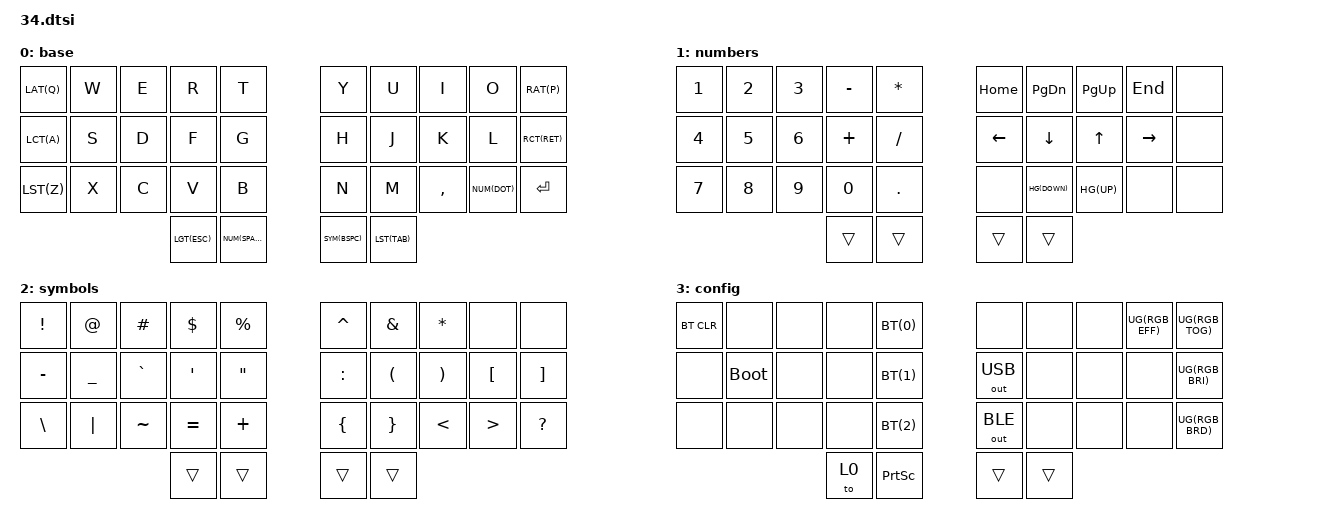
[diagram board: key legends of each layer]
#include <behaviors.dtsi>
#include <dt-bindings/zmk/backlight.h>
#include <dt-bindings/zmk/bt.h>
#include <dt-bindings/zmk/keys.h>
#include <dt-bindings/zmk/outputs.h>
#include <dt-bindings/zmk/rgb.h>

&caps_word {
    continue-list = <UNDERSCORE MINUS BSPC DEL N1 N2 N3 N4 N5 N6 N7 N8 N9 N0>;
};

// hold-prefered: trigger hold when other key is pressed
//      balanced: trigger hold when other key is pressed and released

&mt {
    flavor = "hold-preferred";
    tapping-term-ms = <200>;
    quick-tap-ms = <180>;
};

&lt {
    flavor = "balanced";
    tapping-term-ms = <200>;
    quick-tap-ms = <180>;
};


#define NUM(k1) &lt 1 k1
#define SYM(k1) &lt 2 k1
#define CFG(k1) &lt 3 k1

// alt/opt
#define LAT(k1) &ht LALT k1
#define RAT(k1) &ht RALT k1
// Gui/cmd/win
#define LGT(k1) &ht LGUI k1
// shift
#define LST(k1) &ht LSHFT k1
#define RST(k1) &ht RSHFT k1
// ctrl
#define LCT(k1) &ht LCTRL k1
#define RCT(k1) &ht RCTRL k1
// rgb
#define UG(k1) &rgb_ug k1

// Hold GUI + x key press
#define HG(k1) &kp LG(k1)
#define BT(k1) &bt BT_SEL k1
#define BTC &bt BT_CLR

#define BOOT &bootloader

//     == layout and key index ==
//
// +---------------+---------------+
// | 0  1  2  3  4 |  5  6  7  8  9|
// |10 11 12 13 14 | 15 16 17 18 19|
// |20 21 22 23 24 | 25 26 27 28 29|
// +--------|30 31 | 32 33|--------+
//          +------+------+
/ {
    combos {
        compatible = "zmk,combos";
        combo_bspc {
            bindings = <&kp BACKSPACE>;
            key-positions = <3 4>;
        };

        combo_vol_down {
            bindings = <&kp C_VOL_DN>;
            key-positions = <26 27>;
        };

        combo_vol_up {
            bindings = <&kp C_VOL_UP>;
            key-positions = <27 28>;
        };

        combo_caps_word {
            bindings = <&caps_word>;
            key-positions = <13 16>;
        };
        combo_sticky_ctrl_shift {
            bindings = <&sk LC(LSHFT)>;
            key-positions = <10 20>;
        };
        combo_layer_3 {
            bindings = <&to 3>;
            key-positions = <0 9>;
        };
    };

    behaviors {
        hp: hold_preferred {
            label = "HOLD PREFERRED";
            compatible = "zmk,behavior-hold-tap";
            #binding-cells = <2>;
            flavor = "hold-preferred";
            tapping-term-ms = <200>;
            quick-tap-ms = <180>;
            bindings = <&kp>, <&kp>;
        };
        ht: hold_tap {
            label = "TAP_HOLD";
            compatible = "zmk,behavior-hold-tap";
            #binding-cells = <2>;
            flavor = "balanced";
            tapping-term-ms = <200>;
            quick-tap-ms = <180>;
            bindings = <&kp>, <&kp>;
        };
        td0: td_0 {
            compatible = "zmk,behavior-tap-dance";
            label = "GUI_BACKTICK";
            #binding-cells = <0>;
            tapping-term-ms = <200>;
            bindings = <&kp LG(GRAVE)>;
        };
    };

//############################################################################################################
// * Having enter on left side to hit action when right hand operate mouse
//############################################################################################################

    keymap {
        compatible = "zmk,keymap";
        label = "3x5 keymap";

        base {
            bindings = <
//+---------+---------+---------+---------+---------+/*  */+---------+---------+---------+---------+---------+
   LAT(Q)    &kp W     &kp E     &kp R     &kp T     /*  */ &kp Y     &kp U     &kp I     &kp O     RAT(P)
//+---------+---------+---------+---------+---------+/*  */+---------+---------+---------+---------+---------+
   LCT(A)    &kp S     &kp D     &kp F     &kp G     /*  */ &kp H     &kp J     &kp K     &kp L     RCT(RET)
//+---------+---------+---------+---------+---------+/*  */+---------+---------+---------+---------+---------+
   LST(Z)    &kp X     &kp C     &kp V     &kp B     /*  */ &kp N     &kp M     &kp COMMA NUM(DOT)  &kp RET
//+---------+---------+---------+---------+---------+/*  */+---------+---------+---------+---------+---------+
                                 LGT(ESC)  NUM(SPACE)/*  */ SYM(BSPC) LST(TAB)
                              //================================================
            >;
        };

        numbers {
            bindings = <
//+---------+---------+---------+---------+---------+/*  */+---------+---------+---------+---------+---------+
   &kp N1    &kp N2    &kp N3    &kp MINUS &kp STAR  /*  */ &kp HOME  &kp PG_DN &kp PG_UP &kp END   &none
//+---------+---------+---------+---------+---------+/*  */+---------+---------+---------+---------+---------+
   &kp N4    &kp N5    &kp N6    &kp PLUS  &kp SLASH /*  */ &kp LEFT  &kp DOWN  &kp UP    &kp RIGHT &none
//+---------+---------+---------+---------+---------+/*  */+---------+---------+---------+---------+---------+
   &kp N7    &kp N8    &kp N9    &kp N0    &kp DOT   /*  */ &none     HG(DOWN)  HG(UP)    &none     &none
//+---------+---------+---------+---------+---------+/*  */+---------+---------+---------+---------+---------+
                                 &trans    &trans    /*  */ &trans    &trans
                              //================================================
            >;
        };

        symbols {
            bindings = <
//+---------+---------+---------+---------+---------+/*  */+---------+---------+---------+---------+---------+
   &kp EXCL  &kp AT    &kp HASH  &kp DLLR  &kp PRCNT /*  */ &kp CARET &kp AMPS  &kp STAR  &none     &none
//+---------+---------+---------+---------+---------+/*  */+---------+---------+---------+---------+---------+
   &kp MINUS &kp UNDER &kp GRAVE &kp SQT   &kp DQT   /*  */ &kp COLON &kp LPAR  &kp RPAR  &kp LBKT  &kp RBKT
//+---------+---------+---------+---------+---------+/*  */+---------+---------+---------+---------+---------+
   &kp BSLH  &kp PIPE  &kp TILDE &kp EQUAL &kp PLUS  /*  */ &kp LBRC  &kp RBRC  &kp LT    &kp GT    &kp QMARK
//+---------+---------+---------+---------+---------+/*  */+---------+---------+---------+---------+---------+
                                 &trans    &trans    /*  */ &trans    &trans
                              //================================================
            >;
        };

        config {
            bindings = <
//+---------+---------+---------+------+---------+/*  */+------------+---------+---------+-----------+-----------+
   BTC       &none     &none     &none  BT(0)     /*  */ &none        &none     &none     UG(RGB_EFF) UG(RGB_TOG)
//+---------+---------+---------+------+---------+/*  */+------------+---------+---------+-----------+-----------+
   &none     BOOT      &none     &none  BT(1)     /*  */ &out OUT_USB &none     &none     &none       UG(RGB_BRI)
//+---------+---------+---------+------+---------+/*  */+------------+---------+---------+-----------+-----------+
   &none     &none     &none     &none  BT(2)     /*  */ &out OUT_BLE &none     &none     &none       UG(RGB_BRD)
//+---------+---------+---------+------+---------+/*  */+------------+---------+---------+-----------+-----------+
                                 &to 0  &kp PSCRN /*  */ &trans       &trans
                              //================================================
            >;
        };
    };
};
